# GD32F30x_CL register map
File version: 1.0
CPU: CM4 r2p1, little endian, MPU, FPU, 4 interrupt priority bits
Registers are 32-bit, read-write, reset 0x0 unless marked. A register's access mark holds for its fields unless they carry their own. Offsets are from the block's base; [hi:lo] are bit positions; {n}, {i} and the like mark numbered series; 'fields as' and 'values as' point back to an identical list.

## TIMER9 — General-purpose-timers
Base 0x40015000
Same registers: TIMER12 0x40001C00, TIMER13 0x40002000, TIMER10 0x40015400
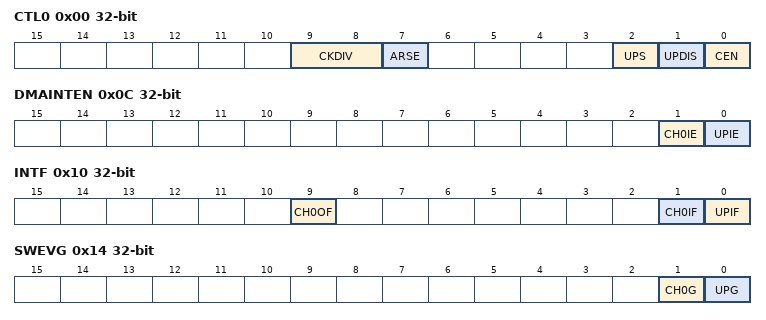
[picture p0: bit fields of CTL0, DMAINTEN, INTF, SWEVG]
0x00 CTL0 — control register 1
  [9:8] CKDIV — Clock division
  [7] ARSE — Auto-reload shadow enable
  [2] UPS — Update source
  [1] UPDIS — Update disable
  [0] CEN — Counter enable
0x0C DMAINTEN — DMA/Interrupt enable register
  [1] CH0IE — Channel 0 capture/compare interrupt enable
  [0] UPIE — Update interrupt enable
0x10 INTF — interrupt flag register
  [9] CH0OF — Channel 0 over capture flag
  [1] CH0IF — Channel 0 capture/compare interrupt flag
  [0] UPIF — Update interrupt flag
0x14 SWEVG wo — event generation register
  [1] CH0G — Channel 0 capture or compare event generation
  [0] UPG — Update generation
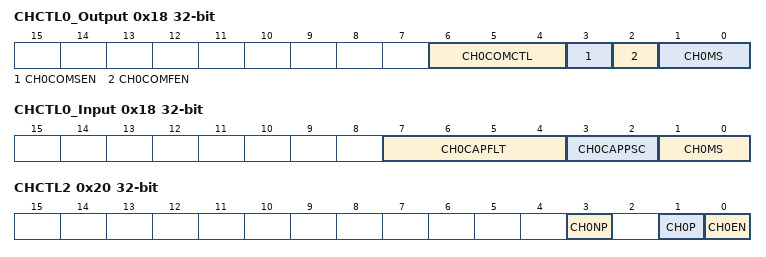
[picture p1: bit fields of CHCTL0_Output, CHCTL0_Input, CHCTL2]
0x18 CHCTL0_Output — Channel control register 0 (output mode)
  [6:4] CH0COMCTL — Channel 0 compare output control
  [3] CH0COMSEN — Channel 0 compare output shadow enable
  [2] CH0COMFEN — Channel 0 output compare fast enable
  [1:0] CH0MS — Channel 0 I/O mode selection
0x18 CHCTL0_Input (alternate view of CHCTL0_Output) — Channel control register 0 ( (input mode)
  [7:4] CH0CAPFLT — Channel 0 input capture filter control
  [3:2] CH0CAPPSC — Channel 0 input capture prescaler
  [1:0] CH0MS — Channel 0 mode selection
0x20 CHCTL2 — Channel control register 2
  [3] CH0NP — Channel 0 complementary output polarity
  [1] CH0P — Channel 0 capture/compare polarity
  [0] CH0EN — Channel 0 capture/compare function enable
0x24 CNT — Counter register
  [15:0] CNT — current counter value
0x28 PSC — Prescaler register
  [15:0] PSC — Prescaler value of the counter clock
0x2C CAR — Counter auto reload register
  [15:0] CARL — Counter auto reload value
0x34 CH0CV — Channel 0 capture/compare value register
  [15:0] CH0VAL — Capture or compare value of channel 0
0x50 IRMP — channel input remap register
  [11:10] ITI1_RMP — Internal trigger input1 remap
0xFC CFG — configuration register
  [1] CHVSEL — Write CHxVAL register selection

## USART0 — Universal synchronous asynchronous receiver transmitter
Base 0x40013800
Same registers: USART1 0x40004400, USART2 0x40004800
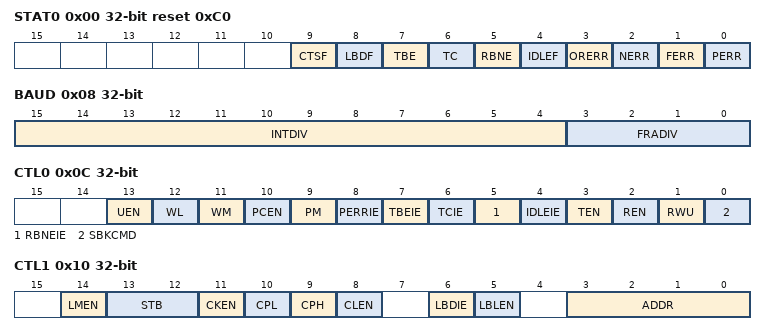
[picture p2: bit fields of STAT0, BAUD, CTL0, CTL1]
0x00 STAT0 ro reset 0xC0 — Status register 0
  [9] CTSF — CTS change flag
  [8] LBDF — LIN break detection flag
  [7] TBE — Transmit data buffer empty
  [6] TC — Transmission complete
  [5] RBNE — Read data buffer not empty
  [4] IDLEF — IDLE frame detected flag
  [3] ORERR — Overrun error
  [2] NERR — Noise error flag
  [1] FERR — Frame error flag
  [0] PERR — Parity error flag
0x04 DATA
  [8:0] DATA — Transmit or read data value
0x08 BAUD — Baud rate register
  [15:4] INTDIV — Integer part of baud-rate divider
  [3:0] FRADIV — Fraction part of baud-rate divider
0x0C CTL0 — Control register 0
  [13] UEN — USART enable
  [12] WL — Word length
  [11] WM — Wakeup method in mute mode
  [10] PCEN — Parity check function enable
  [9] PM — Parity mode
  [8] PERRIE — Parity error interrupt enable
  [7] TBEIE — Transmitter buffer empty interrupt enable
  [6] TCIE — Transmission complete interrupt enable
  [5] RBNEIE — Read data buffer not empty interrupt and overrun error interrupt enable
  [4] IDLEIE — IDLE line detected interrupt enable
  [3] TEN — Transmitter enable
  [2] REN — Receiver enable
  [1] RWU — Receiver wakeup from mute mode
  [0] SBKCMD — Send break command
0x10 CTL1 — Control register 1
  [14] LMEN — LIN mode enable
  [13:12] STB — STOP bits length
  [11] CKEN — CK pin enable
  [10] CPL — Clock polarity
  [9] CPH — Clock phase
  [8] CLEN — CK Length
  [6] LBDIE — LIN break detection interrupt enable
  [5] LBLEN — LIN break frame length
  [3:0] ADDR — Address of the USART
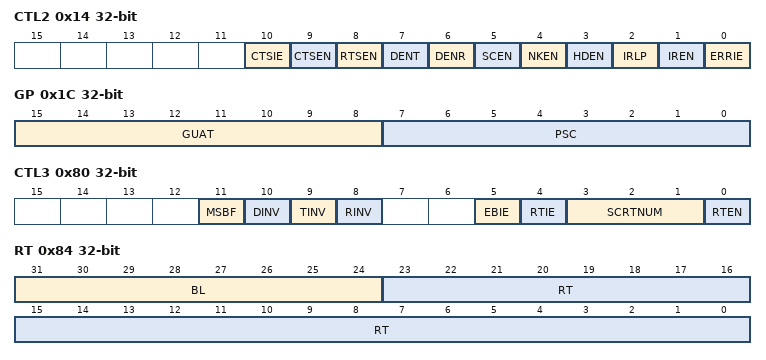
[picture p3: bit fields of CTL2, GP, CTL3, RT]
0x14 CTL2 — Control register 2
  [10] CTSIE — CTS interrupt enable
  [9] CTSEN — CTS enable
  [8] RTSEN — RTS enable
  [7] DENT — DMA request enable for transmission
  [6] DENR — DMA request enable for reception
  [5] SCEN — Smartcard mode enable
  [4] NKEN — Smartcard NACK enable
  [3] HDEN — Half-duplex selection
  [2] IRLP — IrDA low-power
  [1] IREN — IrDA mode enable
  [0] ERRIE — Error interrupt enable
0x1C GP — Guard time and prescaler register
  [15:8] GUAT — Guard time value in Smartcard mode
  [7:0] PSC — Prescaler value
0x80 CTL3 — Control register 3
  [11] MSBF — Most significant bit first
  [10] DINV — Data bit level inversion
  [9] TINV — TX pin level inversion
  [8] RINV — RX pin level inversion
  [5] EBIE — Interrupt enable bit of end of block event
  [4] RTIE — Interrupt enable bit of receive timeout event
  [3:1] SCRTNUM — Smartcard auto-retry number
  [0] RTEN — Receiver timeout enable
0x84 RT — Receiver timeout register
  [31:24] BL — Block Length
  [23:0] RT — Receiver timeout threshold
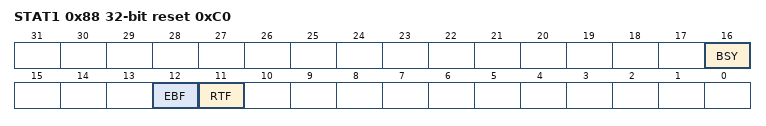
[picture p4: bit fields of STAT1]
0x88 STAT1 access per field reset 0xC0 — Status register 1
  [16] BSY ro — Busy flag
  [12] EBF write — End of block flag
  [11] RTF write — Receiver timeout flag

## UART3 — Universal asynchronous receiver transmitter
Base 0x40004C00
Same registers: UART4 0x40005000
Registers as USART0, without CTL3, RT, STAT1; these are added or differ:
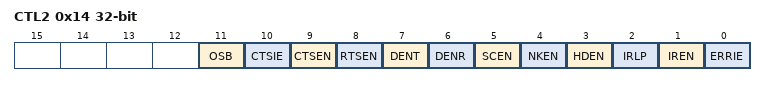
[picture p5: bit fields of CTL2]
0x14 CTL2 — Control register 2
  [11] OSB — One sample bit method enable
  [10] CTSIE — CTS interrupt enable
  [9] CTSEN — CTS enable
  [8] RTSEN — RTS enable
  [7] DENT — DMA request enable for transmission
  [6] DENR — DMA request enable for reception
  [5] SCEN — Smartcard mode enable
  [4] NKEN — Smartcard NACK enable
  [3] HDEN — Half-duplex selection
  [2] IRLP — IrDA low-power
  [1] IREN — IrDA mode enable
  [0] ERRIE — Error interrupt enable

## USBFS_HOST — USB on the go full speed host
Base 0x50000400
0x00 HCTL — host configuration register (HCTL)
  [1:0] CLKSEL — clock select for USB clock
0x04 HFT reset 0xBB80 — Host frame interval register
  [15:0] FRI — Frame interval
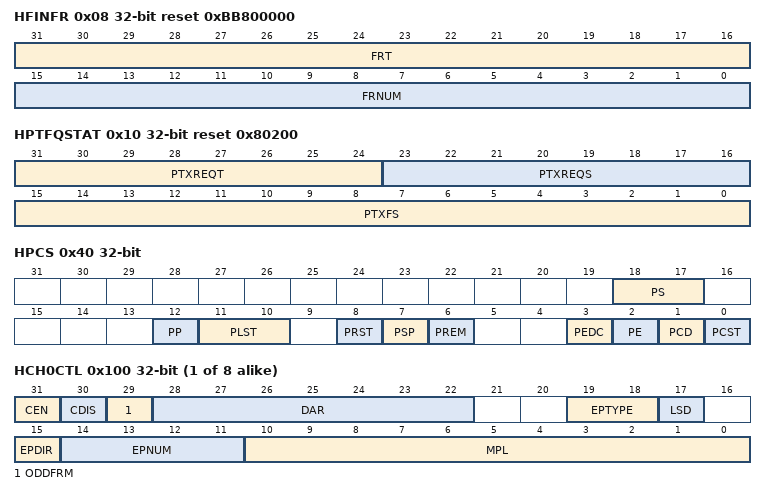
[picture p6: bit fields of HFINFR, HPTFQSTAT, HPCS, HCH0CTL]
0x08 HFINFR ro reset 0xBB800000 — OTG_FS host frame number/frame time remaining register (HFINFR)
  [31:16] FRT — Frame remaining time
  [15:0] FRNUM — Frame number
0x10 HPTFQSTAT ro reset 0x80200 — Host periodic transmit FIFO/queue status register (HPTFQSTAT)
  [31:24] PTXREQT — Top of the periodic transmit request queue
  [23:16] PTXREQS — Periodic transmit request queue space available
  [15:0] PTXFS — Periodic transmit data FIFO space available
0x14 HACHINT ro — Host all channels interrupt register
  [7:0] HACHINT — Host all channel interrupts
0x18 HACHINTEN — host all channels interrupt mask register
  [7:0] CINTEN — Channel interrupt enable
0x40 HPCS access per field — Host port control and status register (USBFS_HPCS)
  [18:17] PS ro — Port speed
  [12] PP rw — Port power
  [11:10] PLST ro — Port line status
  [8] PRST rw — Port reset
  [7] PSP rw — Port suspend
  [6] PREM rw — Port resume
  [3] PEDC rw — Port enable/disable change
  [2] PE rw — Port enable
  [1] PCD rw — Port connect detected
  [0] PCST ro — Port connect status
{0x100+0x20*i} HCH{i}CTL (i=0..7) — host channel-{i} characteristics register (HCH{i}CTL)
  [31] CEN — Channel enable
  [30] CDIS — Channel disable
  [29] ODDFRM — Odd frame
  [28:22] DAR — Device address
  [19:18] EPTYPE — Endpoint type
  [17] LSD — Low-speed device
  [15] EPDIR — Endpoint direction
  [14:11] EPNUM — Endpoint number
  [10:0] MPL — Maximum packet size
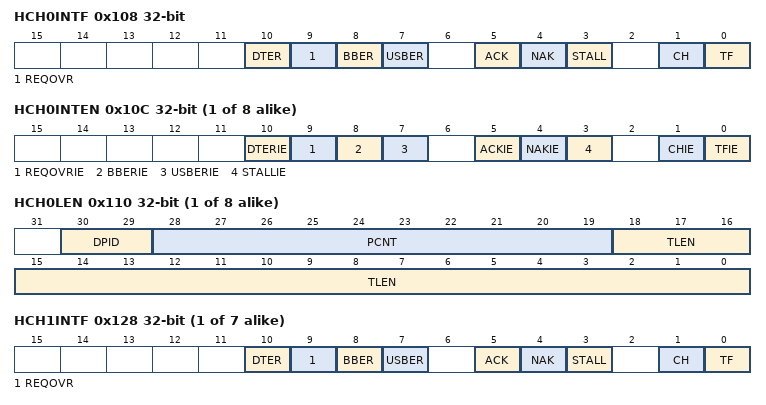
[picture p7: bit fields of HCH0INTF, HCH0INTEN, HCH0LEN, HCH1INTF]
0x108 HCH0INTF — host channel-0 interrupt register (USBFS_HCHxINTF)
  [10] DTER — Data toggle error
  [9] REQOVR — Request queue overrun
  [8] BBER — Babble error
  [7] USBER — USB bus error
  [5] ACK — ACK response received/transmitted interrupt
  [4] NAK — NAK response received interrupt
  [3] STALL — STALL response received interrupt
  [1] CH — Channel halted
  [0] TF — Transfer finished
{0x10C+0x20*i} HCH{i}INTEN (i=0..7) — host channel-{i} interrupt enable register (HCH{i}INTEN)
  [10] DTERIE — Data toggle error interrupt enable
  [9] REQOVRIE — request queue overrun interrupt enable
  [8] BBERIE — Babble error interrupt enable
  [7] USBERIE — USB bus error interrupt enable
  [5] ACKIE — ACK interrupt enable
  [4] NAKIE — NAK interrupt enable
  [3] STALLIE — STALL interrupt enable
  [1] CHIE — Channel halted interrupt enable
  [0] TFIE — Transfer completed interrupt enable
{0x110+0x20*i} HCH{i}LEN (i=0..7) — host channel-{i} transfer length register
  [30:29] DPID — Data PID
  [28:19] PCNT — Packet count
  [18:0] TLEN — Transfer length
{0x108+0x20*i} HCH{i}INTF (i=1..7) — host channel-{i} interrupt register (HCH{i}INTF)
  fields as HCH0INTF

## USBFS_PWRCLK — USB on the go full speed
Base 0x50000E00
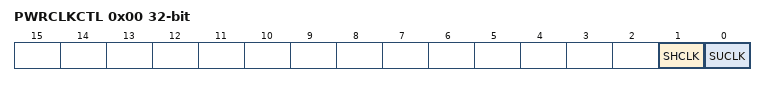
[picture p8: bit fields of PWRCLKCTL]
0x00 PWRCLKCTL — power and clock gating control register (PWRCLKCTL)
  [1] SHCLK — Stop HCLK
  [0] SUCLK — Stop the USB clock

## WWDGT — Window watchdog timer
Base 0x40002C00
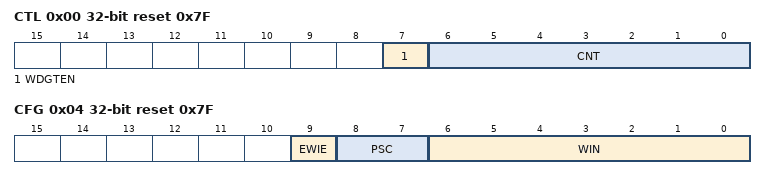
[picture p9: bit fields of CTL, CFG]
0x00 CTL reset 0x7F — Control register
  [7] WDGTEN — Activation bit
  [6:0] CNT — 7-bit counter
0x04 CFG reset 0x7F — Configuration register
  [9] EWIE — Early wakeup interrupt
  [8:7] PSC — Prescaler
  [6:0] WIN — 7-bit window value
0x08 STAT — Status register
  [0] EWIF — Early wakeup interrupt flag
